AUTOSAR XML (schema 4-1-1)
standard types defined: UInt8, UInt32, UInt16, uint8, uint16, uint32
package /SCU/Types
  impl type Array8: category=ARRAY
    element Array8_elementsImpl: array-size=8, array-size-semantics=FIXED-SIZE, implementation-data-type=UInt8
  impl type Array16: category=ARRAY
    element Array16_elementsImpl: array-size=8, array-size-semantics=FIXED-SIZE, implementation-data-type=UInt16
  impl type Array3: category=ARRAY
    element Array3_elementsImpl: array-size=3, array-size-semantics=FIXED-SIZE, implementation-data-type=UInt16
package /SCU/Extract
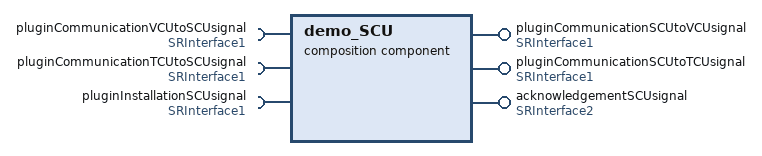
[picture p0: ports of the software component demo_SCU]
  composition sw component type demo_SCU
    require port pluginCommunicationVCUtoSCUsignal: required-interface=SRInterface1
    provide port pluginCommunicationSCUtoVCUsignal: provided-interface=SRInterface1
    require port pluginCommunicationTCUtoSCUsignal: required-interface=SRInterface1
    provide port pluginCommunicationSCUtoTCUsignal: provided-interface=SRInterface1
    require port pluginInstallationSCUsignal: required-interface=SRInterface1
    provide port acknowledgementSCUsignal: provided-interface=SRInterface2
    4 x component:
      PirteSWCProto: type=PirteSWC
      ImuSWCProto: type=ImuSWC
      UltraSWCProto: type=UltraSWC
      IoHwAbService: type=IoHwAb
    connect ImuSWCProto.ImuSwcWriteGyroDataToPirteSwcPort1 -> PirteSWCProto.PirteSwcReadDataFromImuGyroPort7
    connect ImuSWCProto.ImuSwcWriteAcceDataToPirteSwcPort2 -> PirteSWCProto.PirteSwcReadDataFromImuAccePort8
    connect UltraSWCProto.UltraSwcDataOutPort2 -> PirteSWCProto.PirteSwcReadDataFromUltraSwcPort9
    connect IoHwAbService.IoHwGyroDataInPort1 -> ImuSWCProto.ImuSwcToIoHwGyroDataInPort3
    connect IoHwAbService.IoHwAcceDataInPort2 -> ImuSWCProto.ImuSwcToIoHwAcceDataInPort4
    connect IoHwAbService.IoHwUltraDataInPort3 -> UltraSWCProto.UltraSwcDataInPort1
    delegate PirteSWCProto.PirteSwcReadDataFromVCUPort1 <-> outer port pluginCommunicationVCUtoSCUsignal
    delegate PirteSWCProto.PirteSwcWriteDataToVCUPort2 <-> outer port pluginCommunicationSCUtoVCUsignal
    delegate PirteSWCProto.PirteSwcReadCommDataFromTCUPort3 <-> outer port pluginCommunicationTCUtoSCUsignal
    delegate PirteSWCProto.PirteSwcWriteCommDataToTCUPort4 <-> outer port pluginCommunicationSCUtoTCUsignal
    delegate PirteSWCProto.PirteSwcReadInstallDataFromTCUPort5 <-> outer port pluginInstallationSCUsignal
    delegate PirteSWCProto.PirteSwcWriteAckDataToTCUPort6 <-> outer port acknowledgementSCUsignal
  system demo_SCUEcuExtract: category=ECU_EXTRACT
    system mapping ImplementationMappings
      sw-impl-mappings:
        4 x swc to impl mapping:
          PirteSWCProtoMapping: component-implementation=PirteSwcImplementation, component=demo_SCUPrototype.PirteSWCProto
          ImuSWCProtoMapping: component-implementation=ImuSwcImplementation, component=demo_SCUPrototype.ImuSWCProto
          UltraSWCProtoMapping: component-implementation=UltraSwcImplementation, component=demo_SCUPrototype.UltraSWCProto
          IoHwAbServiceMapping: component-implementation=IoHwAbImplementation, component=demo_SCUPrototype.IoHwAbService
    system mapping SignalMappings
      data-mappings:
        data-element=demo_SCUPrototype.pluginCommunicationVCUtoSCUsignal.argInt32, system-signal=pluginCommunicationVCUtoSCUsignalargInt32SSig
        data-element=demo_SCUPrototype.pluginCommunicationSCUtoVCUsignal.argInt32, system-signal=pluginCommunicationSCUtoVCUsignalargInt32SSig
        data-element=demo_SCUPrototype.pluginCommunicationTCUtoSCUsignal.argInt32, system-signal=pluginCommunicationTCUtoSCUsignalargInt32SSig
        data-element=demo_SCUPrototype.pluginCommunicationSCUtoTCUsignal.argInt32, system-signal=pluginCommunicationSCUtoTCUsignalargInt32SSig
        data-element=demo_SCUPrototype.pluginInstallationSCUsignal.argInt32, system-signal=pluginInstallationSCUsignalargInt32SSig
        data-element=demo_SCUPrototype.acknowledgementSCUsignal.acknowledgementVCU, system-signal=acknowledgementSCUsignalacknowledgementVCUSSig
    root-software-compositions:
      root sw composition prototype demo_SCUPrototype: software-composition=demo_SCU
package /SCU/Extract/Communication
  pdu pluginCommunicationVCUtoSCUsignalargInt32IPdu
    signal pluginCommunicationVCUtoSCUsignalargInt32ISig: system signal pluginCommunicationVCUtoSCUsignalargInt32SSig
  pdu pluginCommunicationSCUtoVCUsignalargInt32IPdu
    signal pluginCommunicationSCUtoVCUsignalargInt32ISig: system signal pluginCommunicationSCUtoVCUsignalargInt32SSig
  pdu pluginCommunicationTCUtoSCUsignalargInt32IPdu
    signal pluginCommunicationTCUtoSCUsignalargInt32ISig: system signal pluginCommunicationTCUtoSCUsignalargInt32SSig
  pdu pluginCommunicationSCUtoTCUsignalargInt32IPdu
    signal pluginCommunicationSCUtoTCUsignalargInt32ISig: system signal pluginCommunicationSCUtoTCUsignalargInt32SSig
  pdu pluginInstallationSCUsignalargInt32IPdu
    signal pluginInstallationSCUsignalargInt32ISig: system signal pluginInstallationSCUsignalargInt32SSig
  pdu acknowledgementSCUsignalacknowledgementVCUIPdu
    signal acknowledgementSCUsignalacknowledgementVCUISig: system signal acknowledgementSCUsignalacknowledgementVCUSSig
package /SCU/Components
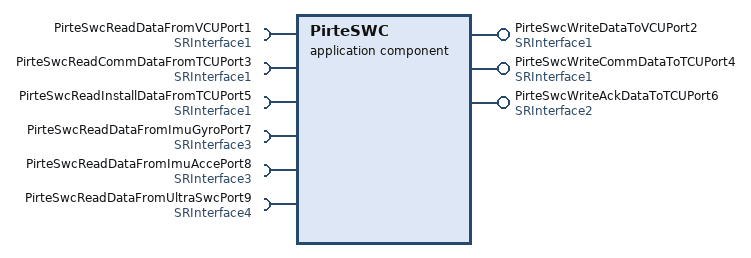
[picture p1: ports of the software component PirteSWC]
  application sw component type PirteSWC
    require port PirteSwcReadDataFromVCUPort1: required-interface=SRInterface1
    provide port PirteSwcWriteDataToVCUPort2: provided-interface=SRInterface1
    require port PirteSwcReadCommDataFromTCUPort3: required-interface=SRInterface1
    provide port PirteSwcWriteCommDataToTCUPort4: provided-interface=SRInterface1
    require port PirteSwcReadInstallDataFromTCUPort5: required-interface=SRInterface1
    provide port PirteSwcWriteAckDataToTCUPort6: provided-interface=SRInterface2
    require port PirteSwcReadDataFromImuGyroPort7: required-interface=SRInterface3
    require port PirteSwcReadDataFromImuAccePort8: required-interface=SRInterface3
    require port PirteSwcReadDataFromUltraSwcPort9: required-interface=SRInterface4
    behavior PirteSwcBehavior: handle-termination-and-restart=NO-SUPPORT
      5 x data received event:
        VCUdataInEvent: start-on-event=SCU_Communication_VCU_ReadRunnable, data=PirteSwcReadDataFromVCUPort1.pluginCommunication
        TCUdataInEvent: start-on-event=SCU_Communication_TCU_ReadRunnable, data=PirteSwcReadCommDataFromTCUPort3.pluginCommunication
        SCUInstallEvent: start-on-event=SCU_Installation_TCU_ReadRunnable, data=PirteSwcReadInstallDataFromTCUPort5.pluginCommunication
        IMUDataInEvent: start-on-event=Pirte_ReadIMUSensor_Runnable, data=PirteSwcReadDataFromImuGyroPort7.dataUInt16
        UltraDataInEvent: start-on-event=Pirte_ReadUltrasonicSensor_Runnable, data=PirteSwcReadDataFromUltraSwcPort9.dataInt32
      8 x runnable, all with minimum-start-interval=1.0:
        SCU_Communication_VCU_ReadRunnable
          data-read-access:
            access dataReadAccess_SCU_Communication_VCU_ReadRunnable_PirteSwcReadDataFromVCUPort1_pluginCommunication: accessed-variable=PirteSwcReadDataFromVCUPort1.pluginCommunication
            access dataReadAccess_SCU_Communication_VCU_ReadRunnable_PirteSwcReadDataFromVCUPort1_argInt32: accessed-variable=PirteSwcReadDataFromVCUPort1.argInt32
        SCU_Communication_VCU_WriteRunnable
          data-write-access:
            access dataWriteAccess_SCU_Communication_VCU_WriteRunnable_PirteSwcWriteDataToVCUPort2_pluginCommunication: accessed-variable=PirteSwcWriteDataToVCUPort2.pluginCommunication
            access dataWriteAccess_SCU_Communication_VCU_WriteRunnable_PirteSwcWriteDataToVCUPort2_argInt32: accessed-variable=PirteSwcWriteDataToVCUPort2.argInt32
        SCU_Communication_TCU_ReadRunnable
          data-read-access:
            access dataReadAccess_SCU_Communication_TCU_ReadRunnable_PirteSwcReadCommDataFromTCUPort3_pluginCommunication: accessed-variable=PirteSwcReadCommDataFromTCUPort3.pluginCommunication
            access dataReadAccess_SCU_Communication_TCU_ReadRunnable_PirteSwcReadCommDataFromTCUPort3_argInt32: accessed-variable=PirteSwcReadCommDataFromTCUPort3.argInt32
        SCU_Communication_TCU_WriteRunnable
          data-write-access:
            access dataWriteAccess_SCU_Communication_TCU_WriteRunnable_PirteSwcWriteCommDataToTCUPort4_pluginCommunication: accessed-variable=PirteSwcWriteCommDataToTCUPort4.pluginCommunication
            access dataWriteAccess_SCU_Communication_TCU_WriteRunnable_PirteSwcWriteCommDataToTCUPort4_argInt32: accessed-variable=PirteSwcWriteCommDataToTCUPort4.argInt32
        SCU_Installation_TCU_ReadRunnable
          data-read-access:
            access dataReadAccess_SCU_Installation_TCU_ReadRunnable_PirteSwcReadInstallDataFromTCUPort5_pluginCommunication: accessed-variable=PirteSwcReadInstallDataFromTCUPort5.pluginCommunication
            access dataReadAccess_SCU_Installation_TCU_ReadRunnable_PirteSwcReadInstallDataFromTCUPort5_argInt32: accessed-variable=PirteSwcReadInstallDataFromTCUPort5.argInt32
        SCU_Installation_TCU_AckRunnable
          data-write-access:
            access dataWriteAccess_SCU_Installation_TCU_AckRunnable_PirteSwcWriteAckDataToTCUPort6_acknowledgementVCU: accessed-variable=PirteSwcWriteAckDataToTCUPort6.acknowledgementVCU
        Pirte_ReadIMUSensor_Runnable
          data-read-access:
            access dataReadAccess_Pirte_ReadIMUSensor_Runnable_PirteSwcReadDataFromImuGyroPort7_dataUInt16: accessed-variable=PirteSwcReadDataFromImuGyroPort7.dataUInt16
            access dataReadAccess_Pirte_ReadIMUSensor_Runnable_PirteSwcReadDataFromImuAccePort8_dataUInt16: accessed-variable=PirteSwcReadDataFromImuAccePort8.dataUInt16
        Pirte_ReadUltrasonicSensor_Runnable
          data-read-access:
            access dataReadAccess_Pirte_ReadUltrasonicSensor_Runnable_PirteSwcReadDataFromUltraSwcPort9_dataInt32: accessed-variable=PirteSwcReadDataFromUltraSwcPort9.dataInt32
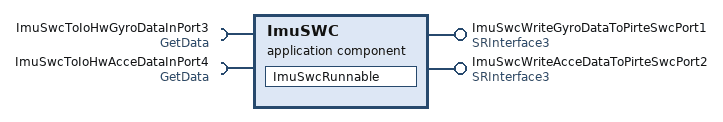
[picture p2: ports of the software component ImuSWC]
  application sw component type ImuSWC
    provide port ImuSwcWriteGyroDataToPirteSwcPort1: provided-interface=SRInterface3
    provide port ImuSwcWriteAcceDataToPirteSwcPort2: provided-interface=SRInterface3
    require port ImuSwcToIoHwGyroDataInPort3: required-interface=GetData
    require port ImuSwcToIoHwAcceDataInPort4: required-interface=GetData
    behavior ImuSwcBehavior: handle-termination-and-restart=NO-SUPPORT
      runnable ImuSwcRunnable: minimum-start-interval=1.0
        data-write-access:
          access dataWriteAccess_ImuSwcRunnable_ImuSwcWriteGyroDataToPirteSwcPort1_dataUInt16: accessed-variable=ImuSwcWriteGyroDataToPirteSwcPort1.dataUInt16
          access dataWriteAccess_ImuSwcRunnable_ImuSwcWriteAcceDataToPirteSwcPort2_dataUInt16: accessed-variable=ImuSwcWriteAcceDataToPirteSwcPort2.dataUInt16
        sync call ImuSwcToIoHwGyroDataInPort3_Read: operation=ImuSwcToIoHwGyroDataInPort3.Read, timeout=0.0
        sync call ImuSwcToIoHwAcceDataInPort4_Read: operation=ImuSwcToIoHwAcceDataInPort4.Read, timeout=0.0
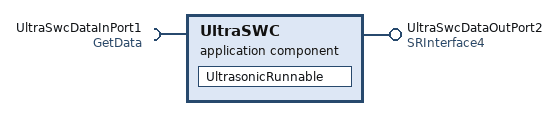
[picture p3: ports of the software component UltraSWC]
  application sw component type UltraSWC
    require port UltraSwcDataInPort1: required-interface=GetData
    provide port UltraSwcDataOutPort2: provided-interface=SRInterface4
    behavior UltraSwcBehavior: handle-termination-and-restart=NO-SUPPORT
      runnable UltrasonicRunnable: minimum-start-interval=1.0
        data-write-access:
          access dataWriteAccess_UltrasonicRunnable_UltraSwcDataOutPort2_dataInt32: accessed-variable=UltraSwcDataOutPort2.dataInt32
        sync call UltraSwcDataInPort1_Read: operation=UltraSwcDataInPort1.Read, timeout=0.0
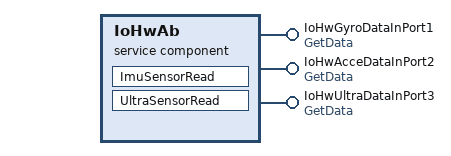
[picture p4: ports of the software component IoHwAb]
  service sw component type IoHwAb
    provide port IoHwGyroDataInPort1: provided-interface=GetData
    provide port IoHwAcceDataInPort2: provided-interface=GetData
    provide port IoHwUltraDataInPort3: provided-interface=GetData
    behavior IoHwAbBehavior: handle-termination-and-restart=NO-SUPPORT
      operation invoked event IoHwGyroDataInPort1_Read: start-on-event=ImuSensorRead, operation=IoHwGyroDataInPort1.Read
      operation invoked event IoHwAcceDataInPort2_Read: start-on-event=ImuSensorRead, operation=IoHwAcceDataInPort2.Read
      operation invoked event IoHwUltraDataInPort3_Read: start-on-event=UltraSensorRead, operation=IoHwUltraDataInPort3.Read
      port-api-options:
        {port-defined-argument-value{value=Array3:0, value-type=Array3}, port=IoHwGyroDataInPort1}
        {port-defined-argument-value{value=Array3:0, value-type=Array3}, port=IoHwAcceDataInPort2}
        {port-defined-argument-value{value=UInt32:0, value-type=UInt32}, port=IoHwUltraDataInPort3}
      runnable ImuSensorRead: minimum-start-interval=1.0, can-be-invoked-concurrently=true
      runnable UltraSensorRead: minimum-start-interval=1.0, can-be-invoked-concurrently=true
  4 x swc implementation, all with programming-language=C, vendor-id=0:
    PirteSwcImplementation: behavior=PirteSwcBehavior
      code-descriptors:
        code src: artifact-descriptors=autosar-engineering-object={short-label=artifactDescriptor, category=artifactDescriptorCategory}
      resource consumption resourceConsumption
    ImuSwcImplementation: behavior=ImuSwcBehavior
      code-descriptors:
        code src: artifact-descriptors=autosar-engineering-object={short-label=artifactDescriptor, category=artifactDescriptorCategory}
      resource consumption resourceConsumption
    UltraSwcImplementation: behavior=UltraSwcBehavior
      code-descriptors:
        code src: artifact-descriptors=autosar-engineering-object={short-label=artifactDescriptor, category=artifactDescriptorCategory}
      resource consumption resourceConsumption
    IoHwAbImplementation: behavior=IoHwAbBehavior
      code-descriptors:
        code src: artifact-descriptors=autosar-engineering-object={short-label=artifactDescriptor, category=artifactDescriptorCategory}
      resource consumption resourceConsumption
package /SCU/Interfaces
  4 x sender receiver interface:
    SRInterface1
      data argInt32: type=UInt32
      data pluginCommunication: type=Array8
    SRInterface2
      data acknowledgementVCU: type=UInt8
    SRInterface3
      data dataUInt16: type=Array3
    SRInterface4
      data dataInt32: type=UInt32
  client server interface GetData: is-service=true
    operation Read: possible-error=[E_OK, E_NOT_OK]
      arg Data: type=Array3, direction=IN
    error E_OK: error-code=0
    error E_NOT_OK: error-code=1
package /BaseTypes
  ecuc value collection SCU
